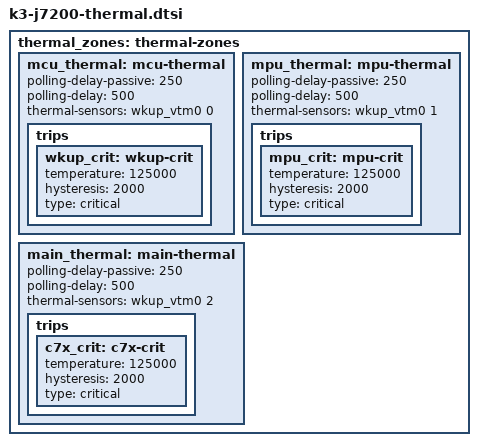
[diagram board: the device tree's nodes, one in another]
// SPDX-License-Identifier: GPL-2.0-only OR MIT
/*
 * Copyright (C) 2023-2024 Texas Instruments Incorporated - https://www.ti.com/
 */

#include <dt-bindings/thermal/thermal.h>

thermal_zones: thermal-zones {
	mcu_thermal: mcu-thermal {
		polling-delay-passive = <250>; /* milliseconds */
		polling-delay = <500>; /* milliseconds */
		thermal-sensors = <&wkup_vtm0 0>;

		trips {
			wkup_crit: wkup-crit {
				temperature = <125000>; /* milliCelsius */
				hysteresis = <2000>; /* milliCelsius */
				type = "critical";
			};
		};
	};

	mpu_thermal: mpu-thermal {
		polling-delay-passive = <250>; /* milliseconds */
		polling-delay = <500>; /* milliseconds */
		thermal-sensors = <&wkup_vtm0 1>;

		trips {
			mpu_crit: mpu-crit {
				temperature = <125000>; /* milliCelsius */
				hysteresis = <2000>; /* milliCelsius */
				type = "critical";
			};
		};
	};

	main_thermal: main-thermal {
		polling-delay-passive = <250>; /* milliseconds */
		polling-delay = <500>; /* milliseconds */
		thermal-sensors = <&wkup_vtm0 2>;

		trips {
			c7x_crit: c7x-crit {
				temperature = <125000>; /* milliCelsius */
				hysteresis = <2000>; /* milliCelsius */
				type = "critical";
			};
		};
	};
};
